AUTOSAR XML (schema 4-2-2)
package /AUTOLIV/SoftwareComponents/BFE
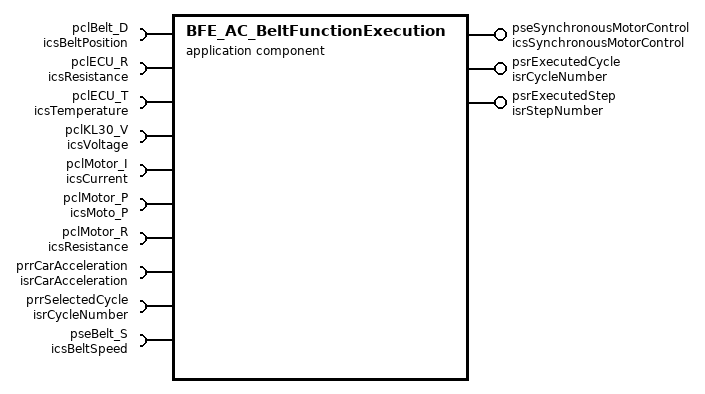
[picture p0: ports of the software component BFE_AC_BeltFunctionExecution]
  application sw component type BFE_AC_BeltFunctionExecution: category=SWC
    10 x require port:
      pclBelt_D: required-com-specs=[GetFromT0_mm, GetFromT0_deg, GetRange_mm, GetRange_deg, GetFromMinPos_deg, GetFromMinPos_mm], required-interface=icsBeltPosition
      pclECU_R: client-com-spec=Get, required-interface=icsResistance
      pclECU_T: required-com-specs=[Init, GetFiltered, Calibrate, GetFiltered_deg], required-interface=icsTemperature
      pclKL30_V: required-com-specs=[Get, Get_2ms, Get_10ms, Get_20ms, Get_100ms], required-interface=icsVoltage
      pclMotor_I: required-com-specs=[Get_mA, Get_A, Get_LSB, ConvertCurrent_mAtoLSB], required-interface=icsCurrent
      pclMotor_P: required-com-specs=[SetPowerOrder, GetPowerOrder], required-interface=icsMoto_P
      pclMotor_R: client-com-spec=Get, required-interface=icsResistance
      prrCarAcceleration: nonqueued-receiver-com-spec{data-element=b8IsCarAccelerationLow, uses-end-to-end-protection=0, init-value=constant-reference=APPLINIT_KB8_CAR_ACCEL_LOW_TRUE}, required-interface=isrCarAcceleration
      prrSelectedCycle: nonqueued-receiver-com-spec{data-element=u8CycleNumber, uses-end-to-end-protection=0, init-value=constant-reference=APPLINIT_KU8_CYCLE_NUMBER_NONE}, required-interface=isrCycleNumber
      pseBelt_S: required-com-specs=[GetSpeed_mm_s, GetSpeed_deg_s], required-interface=icsBeltSpeed
    provide port pseSynchronousMotorControl: provided-interface=icsSynchronousMotorControl
      provided-com-specs:
        operation=ExecuteHighPowerStep, queue-length=1
        operation=ExecuteEmergencyBrakingSequence, queue-length=1
        operation=ResetMotorStageStatus, queue-length=1
    provide port psrExecutedCycle: nonqueued-sender-com-spec{data-element=u8CycleNumber, uses-end-to-end-protection=0, init-value=constant-reference=APPLINIT_KU8_CYCLE_NUMBER_NONE}, provided-interface=isrCycleNumber
    provide port psrExecutedStep: nonqueued-sender-com-spec{data-element=u8StepNumber, uses-end-to-end-protection=1, init-value=constant-reference=APPLINIT_KU8_STEP_NUMBER_NONE}, provided-interface=isrStepNumber
